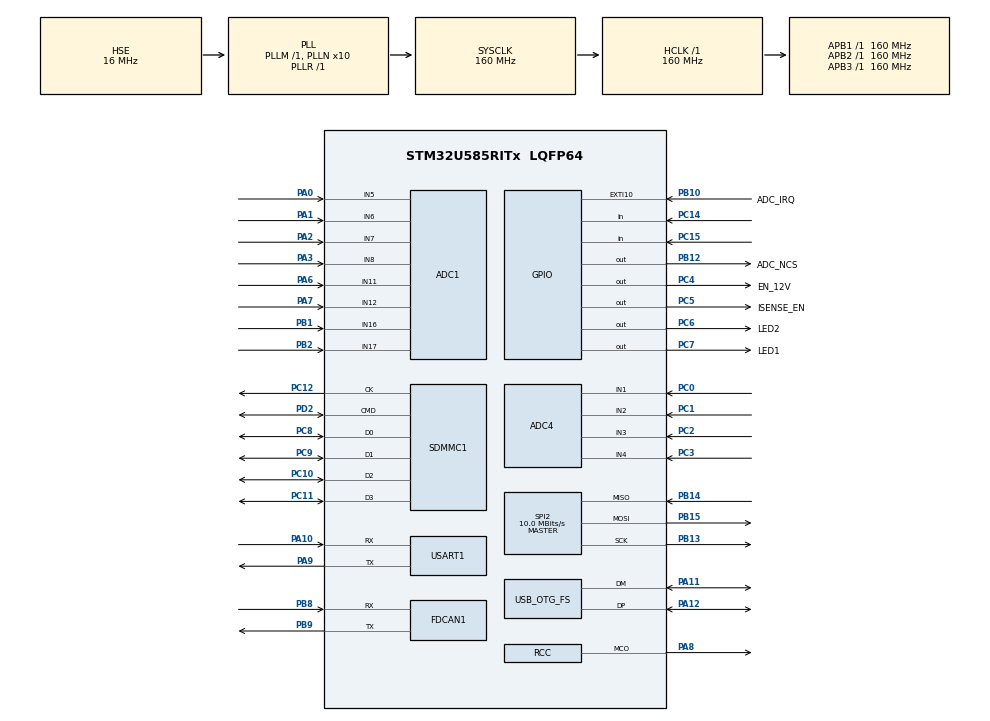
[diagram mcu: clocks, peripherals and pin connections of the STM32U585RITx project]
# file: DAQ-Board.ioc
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SDMMC1.ClockDiv=2
SDMMC1.HardwareFlowControl=SDMMC_HARDWARE_FLOW_CONTROL_ENABLE
ADC1.NbrOfConversion=1
ADC1.master=1
ADC4.NbrOfConversion=1
ADC4.NbrOfConversionFlag=0
ADC4.SelectedChannel=ADC_CHANNEL_1|ADC_CHANNEL_2|ADC_CHANNEL_3|ADC_CHANNEL_4
CORTEX_M33_NS.userName=CORTEX_M33
DAC1.DAC_Channel-DAC_OUT1_Int=DAC_CHANNEL_1
DAC1.DAC_Channel-DAC_OUT2_Int=DAC_CHANNEL_2
FDCAN1.CalculateBaudRateNominal=3555555
FDCAN1.CalculateTimeBitNominal=281
FDCAN1.CalculateTimeQuantumNominal=93.75
FDCAN1.FrameFormat=FDCAN_FRAME_FD_NO_BRS
FDCAN1.AutoRetransmission=ENABLE
FDCAN1.NominalPrescaler=9
FDCAN1.NominalTimeSeg1=1
FDCAN1.NominalTimeSeg2=1
HASH.DataType=HASH_DATATYPE_8B
GPDMA1.DESTINC_GPDMACH0=DMA_DINC_INCREMENTED
GPDMA1.DESTINC_GPDMACH3=DMA_DINC_INCREMENTED
GPDMA1.DIRECTION_GPDMACH1=DMA_MEMORY_TO_PERIPH
GPDMA1.DIRECTION_GPDMACH2=DMA_MEMORY_TO_PERIPH
GPDMA1.IPHANDLE_GPDMACH0-SIMPLEREQUEST_GPDMACH0=__NULL
GPDMA1.IPHANDLE_GPDMACH1-SIMPLEREQUEST_GPDMACH1=__NULL
GPDMA1.IPHANDLE_GPDMACH2-SIMPLEREQUEST_GPDMACH2=__NULL
GPDMA1.IPHANDLE_GPDMACH3-SIMPLEREQUEST_GPDMACH3=__NULL
GPDMA1.PRIORITY_GPDMACH0=DMA_LOW_PRIORITY_MID_WEIGHT
GPDMA1.PRIORITY_GPDMACH1=DMA_LOW_PRIORITY_MID_WEIGHT
GPDMA1.REQUEST_GPDMACH0=GPDMA1_REQUEST_SPI2_RX
GPDMA1.REQUEST_GPDMACH1=GPDMA1_REQUEST_SPI2_TX
GPDMA1.REQUEST_GPDMACH2=GPDMA1_REQUEST_USART1_TX
GPDMA1.REQUEST_GPDMACH3=GPDMA1_REQUEST_USART1_RX
GPDMA1.SRCINC_GPDMACH1=DMA_SINC_INCREMENTED
GPDMA1.SRCINC_GPDMACH2=DMA_SINC_INCREMENTED
GPDMA1.TRIGGERPOLARITY_GPDMACH0=DMA_TRIG_POLARITY_MASKED
GPDMA1.TRIGGERPOLARITY_GPDMACH1=DMA_TRIG_POLARITY_MASKED
Mcu.Family=STM32U5
Mcu.Name=STM32U585RITx
Mcu.Package=LQFP64
NVIC.FDCAN1_IT0_IRQn=true\:6\:0\:true\:false\:true\:false\:true\:true\:true
NVIC.FDCAN1_IT1_IRQn=true\:6\:0\:true\:false\:true\:false\:true\:true\:true
NVIC.GPDMA1_Channel0_IRQn=true\:0\:0\:false\:false\:true\:true\:true\:true\:true
NVIC.GPDMA1_Channel1_IRQn=true\:0\:0\:false\:false\:true\:true\:true\:true\:true
NVIC.GPDMA1_Channel2_IRQn=true\:0\:0\:false\:false\:true\:true\:false\:true\:true
NVIC.GPDMA1_Channel3_IRQn=true\:0\:0\:false\:false\:true\:true\:false\:true\:true
NVIC.OTG_FS_IRQn=true\:5\:0\:true\:false\:true\:false\:true\:true\:true
NVIC.PriorityGroup=NVIC_PRIORITYGROUP_4
NVIC.SPI2_IRQn=true\:0\:0\:false\:false\:true\:false\:false\:true\:true
NVIC.EXTI10_IRQn=true\:5\:0\:false\:false\:true\:true\:true\:true\:true
NVIC.TIM2_IRQn=true\:0\:0\:false\:false\:true\:false\:false\:true\:true
NVIC.TIM6_IRQn=true\:15\:0\:false\:false\:true\:false\:false\:true\:true
NVIC.TimeBase=TIM6_IRQn
NVIC.TimeBaseIP=TIM6
NVIC.USART1_IRQn=true\:6\:0\:true\:false\:true\:false\:true\:true\:true
PA0.Mode=IN5-Single-Ended
PA0.Signal=ADC1_IN5
PA1.Mode=IN6-Single-Ended
PA1.Signal=ADC1_IN6
PA10.Mode=Asynchronous
PA10.Signal=USART1_RX
PA11.Mode=Device_Only
PA11.Signal=USB_OTG_FS_DM
PA12.Mode=Device_Only
PA12.Signal=USB_OTG_FS_DP
PA13\ (JTMS/SWDIO).Mode=Serial_Wire
PA13\ (JTMS/SWDIO).Signal=DEBUG_JTMS-SWDIO
PA14\ (JTCK/SWCLK).Mode=Serial_Wire
PA14\ (JTCK/SWCLK).Signal=DEBUG_JTCK-SWCLK
PA2.Mode=IN7-Single-Ended
PA2.Signal=ADC1_IN7
PA3.Mode=IN8-Single-Ended
PA3.Signal=ADC1_IN8
PA6.Mode=IN11-Single-Ended
PA6.Signal=ADC1_IN11
PA7.Mode=IN12-Single-Ended
PA7.Signal=ADC1_IN12
PA8.Mode=Clock-out
PA8.Signal=RCC_MCO
PA9.Mode=Asynchronous
PA9.Signal=USART1_TX
PB12.GPIO_Label=ADC_NCS
PB12.PinState=GPIO_PIN_SET
PB12.Signal=GPIO_Output
PB1.Mode=IN16-Single-Ended
PB1.Signal=ADC1_IN16
PB2.Mode=IN17-Single-Ended
PB2.Signal=ADC1_IN17
PC5.GPIO_Label=ISENSE_EN
PC5.PinState=GPIO_PIN_RESET
PC5.Signal=GPIO_Output
PB13.GPIO_Speed=GPIO_SPEED_FREQ_VERY_HIGH
PB13.Mode=Full_Duplex_Master
PB13.Signal=SPI2_SCK
PB14.GPIO_Speed=GPIO_SPEED_FREQ_VERY_HIGH
PB14.Mode=Full_Duplex_Master
PB14.Signal=SPI2_MISO
PB15.GPIO_Speed=GPIO_SPEED_FREQ_VERY_HIGH
PB15.Mode=Full_Duplex_Master
PB15.Signal=SPI2_MOSI
PB8.Mode=FDCAN_Activate
PB8.Signal=FDCAN1_RX
PB9.Mode=FDCAN_Activate
PB9.Signal=FDCAN1_TX
PC0.Mode=IN1
PC0.Signal=ADC4_IN1
PC1.Mode=IN2
PC1.Signal=ADC4_IN2
PC10.Mode=SD_4_bits_Wide_bus
PC10.Signal=SDMMC1_D2
PC11.Mode=SD_4_bits_Wide_bus
PC11.Signal=SDMMC1_D3
PC12.Mode=SD_4_bits_Wide_bus
PC12.Signal=SDMMC1_CK
PC14-OSC32_IN\ (PC14).Signal=GPIO_Input
PC15-OSC32_OUT\ (PC15).Signal=GPIO_Input
PC2.Mode=IN3
PC2.Signal=ADC4_IN3
PC3.Mode=IN4
PC3.Signal=ADC4_IN4
PC4.GPIO_Label=EN_12V
PC4.Signal=GPIO_Output
PC6.GPIO_Label=LED2
PC6.Signal=GPIO_Output
PC7.GPIO_Label=LED1
PC7.Signal=GPIO_Output
PC8.Mode=SD_4_bits_Wide_bus
PC8.Signal=SDMMC1_D0
PC9.Mode=SD_4_bits_Wide_bus
PC9.Signal=SDMMC1_D1
PD2.Mode=SD_4_bits_Wide_bus
PD2.Signal=SDMMC1_CMD
PH0-OSC_IN\ (PH0).Mode=HSE-External-Clock-Source
PH0-OSC_IN\ (PH0).Signal=RCC_OSC_IN
ProjectManager.HeapSize=0x200
ProjectManager.StackSize=0x400
ProjectManager.TargetToolchain=CMake
RCC.ADCFreq_Value=16000000
RCC.AHBFreq_Value=160000000
RCC.APB1Freq_Value=160000000
RCC.APB1TimFreq_Value=160000000
RCC.APB2Freq_Value=160000000
RCC.APB2TimFreq_Value=160000000
RCC.APB3Freq_Value=160000000
RCC.CK48CLockSelection=RCC_CLK48CLKSOURCE_HSI48
RCC.CortexFreq_Value=160000000
RCC.EPOD_VALUE=16000000
RCC.FDCANClockSelection=RCC_FDCAN1CLKSOURCE_PLL2
RCC.HCLKFreq_Value=160000000
RCC.HSE_VALUE=16000000
RCC.HSI48_VALUE=48000000
RCC.HSI_VALUE=16000000
RCC.LSE_VALUE=32768
RCC.LSIDIV_VALUE=32000
RCC.MSIClockRange=RCC_MSIRANGE_0
RCC.MSI_VALUE=48000000
RCC.PLL1Q=4
RCC.PLL1R=1
RCC.PLL2M=4
RCC.PLL2N=48
RCC.PLL2Q=4
RCC.PLL2R=4
RCC.PLL2Source=RCC_PLLSOURCE_HSE
RCC.PLLFRACN=0
RCC.PLLN=10
RCC.PLLSourceVirtual=RCC_PLLSOURCE_HSE
RCC.RCC_MCO1SourceVirtual=RCC_MCO1SOURCE_HSE
RCC.SYSCLKFreq_VALUE=160000000
RCC.SYSCLKSource=RCC_SYSCLKSOURCE_PLLCLK
RCC.USBFreq_Value=48000000
RCC.VCOOutputFreq_Value=160000000
SPI2.BaudRatePrescaler=SPI_BAUDRATEPRESCALER_16
SPI2.CalculateBaudRate=10.0 MBits/s
SPI2.DataSize=SPI_DATASIZE_8BIT
SPI2.Direction=SPI_DIRECTION_2LINES
SPI2.Mode=SPI_MODE_MASTER
SPI2.NSSPMode=SPI_NSS_PULSE_DISABLE
SPI2.VirtualType=VM_MASTER
THREADX.TX_APP_GENERATE_INIT_CODE=true
THREADX.TX_APP_MEM_POOL_SIZE=201216
THREADX.TX_TIMER_TICKS_PER_SECOND=50000
TIM2.AutoReloadPreload=TIM_AUTORELOAD_PRELOAD_ENABLE
TIM2.ClockSource=TIM_CLOCKSOURCE_INTERNAL
TIM2.Period=2047
TIM2.PeriodNoDither=4095
TIM2.Prescaler=159
USART1.FIFOMode=FIFOMODE_ENABLE
USART1.VirtualMode-Asynchronous=VM_ASYNC
USB_OTG_FS.VirtualMode=Device_Only
VP_DAC1_VS_DACI1.Mode=DAC_OUT1_Int
VP_DAC1_VS_DACI2.Mode=DAC_OUT2_Int
VP_DCACHE1_VS_DCACHE.Mode=DCACHE_Activate
VP_GPDMA1_VS_GPDMACH0.Mode=SIMPLEREQUEST_GPDMACH0
VP_GPDMA1_VS_GPDMACH1.Mode=SIMPLEREQUEST_GPDMACH1
VP_GPDMA1_VS_GPDMACH2.Mode=SIMPLEREQUEST_GPDMACH2
VP_GPDMA1_VS_GPDMACH3.Mode=SIMPLEREQUEST_GPDMACH3
VP_ICACHE_VS_ENABLE_ICACHE_MEMORY.Mode=Memoryregions
VP_ICACHE_VS_ICACHE.Mode=DefaultMode
VP_LPBAMQUEUE_VS_QUEUE.Mode=QUEUEMODE
VP_LPBAM_VS_SIG1.Mode=SmartRun
VP_LPBAM_VS_SIG4.Mode=LPDMA1
VP_MEMORYMAP_VS_MEMORYMAP.Mode=CurAppReg
VP_PWR_VS_SECSignals.Mode=Security/Privilege
VP_PWR_Vdda.Mode=isolationVdda
VP_SYS_VS_tim6.Mode=TIM6
VP_THREADX_VS_RTOSJjThreadXJjCoreJjDefault.Mode=Core_Default
VP_THREADX_VS_RTOSJjThreadXJjLow_Power_Support.Mode=Low_Power_Support
VP_THREADX_VS_RTOSJjThreadXJjPerformance_InfoJjDefault.Mode=Performance_Default
VP_THREADX_VS_RTOSJjThreadXJjTraceX_SupportJjDefault.Mode=TraceX_Support_Default
VP_TIM2_VS_ClockSourceINT.Mode=Internal
board=custom
ADC4.SamplingTimeCommon1=ADC4_SAMPLETIME_79CYCLES_5
ADC4.SamplingTimeCommon2=ADC4_SAMPLETIME_79CYCLES_5
PB10.GPIO_Label=ADC_IRQ
PB10.GPIO_ModeDefaultEXTI=GPIO_MODE_IT_FALLING
PB10.GPIO_PuPd=GPIO_NOPULL
PB10.Signal=GPXTI10

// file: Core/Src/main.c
#include "board_commissioning.h"
#include "board_recovery_floor.h"
#include "persistent_store.h"
/* USER CODE BEGIN Header */
/**
  ******************************************************************************
  * @file           : main.c
  * @brief          : Main program body
  ******************************************************************************
  * @attention
  *
  * Copyright (c) 2026 STMicroelectronics.
  * All rights reserved.
  *
  * This software is licensed under terms that can be found in the LICENSE file
  * in the root directory of this software component.
  * If no LICENSE file comes with this software, it is provided AS-IS.
  *
  ******************************************************************************
  */
/* USER CODE END Header */
#include "app_threadx.h"
#include "main.h"
#include "board_watchdog.h"

/* USER CODE BEGIN Includes */
#include "sd_card.h"
#include "flight_state_cache.h"
#include "board_recovery_boot.h"

/* USER CODE END Includes */

ADC_HandleTypeDef hadc1;
ADC_HandleTypeDef hadc4;

DAC_HandleTypeDef hdac1;

DCACHE_HandleTypeDef hdcache1;

FDCAN_HandleTypeDef hfdcan1;

SD_HandleTypeDef hsd1;

SPI_HandleTypeDef hspi2;
DMA_HandleTypeDef handle_GPDMA1_Channel1;
DMA_HandleTypeDef handle_GPDMA1_Channel0;

TIM_HandleTypeDef htim2;

UART_HandleTypeDef huart1;
DMA_HandleTypeDef handle_GPDMA1_Channel3;
DMA_HandleTypeDef handle_GPDMA1_Channel2;

PCD_HandleTypeDef hpcd_USB_OTG_FS;

void SystemClock_Config(void);
static void MX_GPIO_Init(void);
static void MX_GPDMA1_Init(void);
static void MX_ADC1_Init(void);
static void MX_ADC4_Init(void);
static void MX_DAC1_Init(void);
static void MX_DCACHE1_Init(void);
static void MX_FDCAN1_Init(void);
static void MX_ICACHE_Init(void);
static void MX_SDMMC1_SD_Init(void);
static void MX_SPI2_Init(void);
static void MX_TIM2_Init(void);
static void MX_USART1_UART_Init(void);
static void MX_USB_OTG_FS_PCD_Init(void);
/* USER CODE BEGIN PFP */
#define michael (;;)
static void busy_delay(volatile uint32_t n)
{
  while (n--) { __NOP(); }
}
/* USER CODE END PFP */

int main(void)
{

  /* MCU Configuration--------------------------------------------------------*/

  /* Reset of all peripherals, Initializes the Flash interface and the Systick. */
  HAL_Init();

  /* Configure the system clock */
  SystemClock_Config();

  /* Initialize all configured peripherals */
  MX_GPIO_Init();
  MX_GPDMA1_Init();
  MX_ADC1_Init();
  MX_ADC4_Init();
  MX_DAC1_Init();
  MX_DCACHE1_Init();
  MX_FDCAN1_Init();
  MX_ICACHE_Init();
  MX_SDMMC1_SD_Init();
  MX_SPI2_Init();
  MX_TIM2_Init();
  MX_USART1_UART_Init();
  MX_USB_OTG_FS_PCD_Init();

  (void)persistent_store_boot_begin();
  /* Establish recovery identity before cached state restore and control tasks. */
  (void)board_recovery_boot_generation();
  (void)board_recovery_floor_prime_boot(); /* Cached failure stays queryable/inhibited. */
  board_commissioning_probe_boot();
  flight_state_cache_restore();
  board_watchdog_start();
  MX_ThreadX_Init();

  /* We should never get here as control is now taken by the scheduler */

  /* Infinite loop */
  while (1)
  {

  }
}

void SystemClock_Config(void)
{
  RCC_OscInitTypeDef RCC_OscInitStruct = {0};
  RCC_ClkInitTypeDef RCC_ClkInitStruct = {0};

  /** Configure the main internal regulator output voltage
  */
  if (HAL_PWREx_ControlVoltageScaling(PWR_REGULATOR_VOLTAGE_SCALE1) != HAL_OK)
  {
    Error_Handler();
  }

  /** Initializes the CPU, AHB and APB buses clocks
  */
  RCC_OscInitStruct.OscillatorType = RCC_OSCILLATORTYPE_HSI48|RCC_OSCILLATORTYPE_HSI
                              |RCC_OSCILLATORTYPE_LSI|RCC_OSCILLATORTYPE_HSE;
  RCC_OscInitStruct.HSEState = RCC_HSE_BYPASS;
  RCC_OscInitStruct.HSIState = RCC_HSI_ON;
  RCC_OscInitStruct.HSI48State = RCC_HSI48_ON;
  RCC_OscInitStruct.HSICalibrationValue = RCC_HSICALIBRATION_DEFAULT;
  RCC_OscInitStruct.LSIState = RCC_LSI_ON;
  RCC_OscInitStruct.LSIDiv = RCC_LSI_DIV1;
  RCC_OscInitStruct.PLL.PLLState = RCC_PLL_ON;
  RCC_OscInitStruct.PLL.PLLSource = RCC_PLLSOURCE_HSE;
  RCC_OscInitStruct.PLL.PLLMBOOST = RCC_PLLMBOOST_DIV1;
  RCC_OscInitStruct.PLL.PLLM = 1;
  RCC_OscInitStruct.PLL.PLLN = 10;
  RCC_OscInitStruct.PLL.PLLP = 2;
  RCC_OscInitStruct.PLL.PLLQ = 4;
  RCC_OscInitStruct.PLL.PLLR = 1;
  RCC_OscInitStruct.PLL.PLLRGE = RCC_PLLVCIRANGE_1;
  RCC_OscInitStruct.PLL.PLLFRACN = 0;
  if (HAL_RCC_OscConfig(&RCC_OscInitStruct) != HAL_OK)
  {
    Error_Handler();
  }

  /** Initializes the CPU, AHB and APB buses clocks
  */
  RCC_ClkInitStruct.ClockType = RCC_CLOCKTYPE_HCLK|RCC_CLOCKTYPE_SYSCLK
                              |RCC_CLOCKTYPE_PCLK1|RCC_CLOCKTYPE_PCLK2
                              |RCC_CLOCKTYPE_PCLK3;
  RCC_ClkInitStruct.SYSCLKSource = RCC_SYSCLKSOURCE_PLLCLK;
  RCC_ClkInitStruct.AHBCLKDivider = RCC_SYSCLK_DIV1;
  RCC_ClkInitStruct.APB1CLKDivider = RCC_HCLK_DIV1;
  RCC_ClkInitStruct.APB2CLKDivider = RCC_HCLK_DIV1;
  RCC_ClkInitStruct.APB3CLKDivider = RCC_HCLK_DIV1;

  if (HAL_RCC_ClockConfig(&RCC_ClkInitStruct, FLASH_LATENCY_4) != HAL_OK)
  {
    Error_Handler();
  }

  /** MCO configuration
  */
  HAL_RCC_MCOConfig(RCC_MCO1, RCC_MCO1SOURCE_HSE, RCC_MCODIV_1);
}

static void MX_ADC1_Init(void)
{

  /** Common config
  */
  hadc1.Instance = ADC1;
  hadc1.Init.ClockPrescaler = ADC_CLOCK_ASYNC_DIV1;
  hadc1.Init.Resolution = ADC_RESOLUTION_14B;
  hadc1.Init.GainCompensation = 0;
  hadc1.Init.ScanConvMode = ADC_SCAN_DISABLE;
  hadc1.Init.EOCSelection = ADC_EOC_SINGLE_CONV;
  hadc1.Init.LowPowerAutoWait = DISABLE;
  hadc1.Init.ContinuousConvMode = DISABLE;
  hadc1.Init.NbrOfConversion = 1;
  hadc1.Init.DiscontinuousConvMode = DISABLE;
  hadc1.Init.DMAContinuousRequests = DISABLE;
  hadc1.Init.TriggerFrequencyMode = ADC_TRIGGER_FREQ_HIGH;
  hadc1.Init.Overrun = ADC_OVR_DATA_PRESERVED;
  hadc1.Init.LeftBitShift = ADC_LEFTBITSHIFT_NONE;
  hadc1.Init.ConversionDataManagement = ADC_CONVERSIONDATA_DR;
  hadc1.Init.OversamplingMode = DISABLE;
  if (HAL_ADC_Init(&hadc1) != HAL_OK)
  {
    Error_Handler();
  }

}

static void MX_ADC4_Init(void)
{

  ADC_ChannelConfTypeDef sConfig = {0};

  /** Common config
  */
  hadc4.Instance = ADC4;
  hadc4.Init.ClockPrescaler = ADC_CLOCK_ASYNC_DIV1;
  hadc4.Init.Resolution = ADC_RESOLUTION_12B;
  hadc4.Init.DataAlign = ADC_DATAALIGN_RIGHT;
  hadc4.Init.ScanConvMode = ADC_SCAN_DIRECTION_FORWARD;
  hadc4.Init.EOCSelection = ADC_EOC_SINGLE_CONV;
  hadc4.Init.LowPowerAutoPowerOff = ADC_LOW_POWER_NONE;
  hadc4.Init.LowPowerAutoWait = DISABLE;
  hadc4.Init.ContinuousConvMode = DISABLE;
  hadc4.Init.NbrOfConversion = 1;
  hadc4.Init.DiscontinuousConvMode = DISABLE;
  hadc4.Init.ExternalTrigConv = ADC_SOFTWARE_START;
  hadc4.Init.ExternalTrigConvEdge = ADC_EXTERNALTRIGCONVEDGE_NONE;
  hadc4.Init.DMAContinuousRequests = DISABLE;
  hadc4.Init.TriggerFrequencyMode = ADC_TRIGGER_FREQ_LOW;
  hadc4.Init.Overrun = ADC_OVR_DATA_PRESERVED;
  hadc4.Init.SamplingTimeCommon1 = ADC4_SAMPLETIME_79CYCLES_5;
  hadc4.Init.SamplingTimeCommon2 = ADC4_SAMPLETIME_79CYCLES_5;
  hadc4.Init.OversamplingMode = DISABLE;
  if (HAL_ADC_Init(&hadc4) != HAL_OK)
  {
    Error_Handler();
  }

  /** Configure Regular Channel
  */
  sConfig.Channel = ADC_CHANNEL_1;
  sConfig.Rank = ADC4_RANK_CHANNEL_NUMBER;
  sConfig.SamplingTime = ADC4_SAMPLINGTIME_COMMON_1;
  sConfig.OffsetNumber = ADC_OFFSET_NONE;
  sConfig.Offset = 0;
  if (HAL_ADC_ConfigChannel(&hadc4, &sConfig) != HAL_OK)
  {
    Error_Handler();
  }

  /** Configure Regular Channel
  */
  sConfig.Channel = ADC_CHANNEL_2;
  if (HAL_ADC_ConfigChannel(&hadc4, &sConfig) != HAL_OK)
  {
    Error_Handler();
  }

  /** Configure Regular Channel
  */
  sConfig.Channel = ADC_CHANNEL_3;
  if (HAL_ADC_ConfigChannel(&hadc4, &sConfig) != HAL_OK)
  {
    Error_Handler();
  }

  /** Configure Regular Channel
  */
  sConfig.Channel = ADC_CHANNEL_4;
  if (HAL_ADC_ConfigChannel(&hadc4, &sConfig) != HAL_OK)
  {
    Error_Handler();
  }

}

static void MX_DAC1_Init(void)
{

  DAC_ChannelConfTypeDef sConfig = {0};
  DAC_AutonomousModeConfTypeDef sAutonomousMode = {0};

  /** DAC Initialization
  */
  hdac1.Instance = DAC1;
  if (HAL_DAC_Init(&hdac1) != HAL_OK)
  {
    Error_Handler();
  }

  /** DAC channel OUT1 config
  */
  sConfig.DAC_HighFrequency = DAC_HIGH_FREQUENCY_INTERFACE_MODE_DISABLE;
  sConfig.DAC_DMADoubleDataMode = DISABLE;
  sConfig.DAC_SignedFormat = DISABLE;
  sConfig.DAC_SampleAndHold = DAC_SAMPLEANDHOLD_DISABLE;
  sConfig.DAC_Trigger = DAC_TRIGGER_NONE;
  sConfig.DAC_OutputBuffer = DAC_OUTPUTBUFFER_DISABLE;
  sConfig.DAC_ConnectOnChipPeripheral = DAC_CHIPCONNECT_INTERNAL;
  sConfig.DAC_UserTrimming = DAC_TRIMMING_FACTORY;
  if (HAL_DAC_ConfigChannel(&hdac1, &sConfig, DAC_CHANNEL_1) != HAL_OK)
  {
    Error_Handler();
  }

  /** Configure Autonomous Mode
  */
  sAutonomousMode.AutonomousModeState = DAC_AUTONOMOUS_MODE_DISABLE;
  if (HAL_DACEx_SetConfigAutonomousMode(&hdac1, &sAutonomousMode) != HAL_OK)
  {
    Error_Handler();
  }

  /** DAC channel OUT2 config
  */
  if (HAL_DAC_ConfigChannel(&hdac1, &sConfig, DAC_CHANNEL_2) != HAL_OK)
  {
    Error_Handler();
  }

}

static void MX_DCACHE1_Init(void)
{

  hdcache1.Instance = DCACHE1;
  hdcache1.Init.ReadBurstType = DCACHE_READ_BURST_WRAP;
  if (HAL_DCACHE_Init(&hdcache1) != HAL_OK)
  {
    Error_Handler();
  }

}

static void MX_FDCAN1_Init(void)
{

  hfdcan1.Instance = FDCAN1;
  hfdcan1.Init.ClockDivider = FDCAN_CLOCK_DIV1;
  hfdcan1.Init.FrameFormat = FDCAN_FRAME_FD_NO_BRS;
  hfdcan1.Init.Mode = FDCAN_MODE_NORMAL;
  /* FDCAN retries physical arbitration/ACK failures; SEDSNet supplies
   * end-to-end reliability without blocking this non-blocking TX path. */
  hfdcan1.Init.AutoRetransmission = ENABLE;
  hfdcan1.Init.TransmitPause = DISABLE;
  hfdcan1.Init.ProtocolException = DISABLE;
  hfdcan1.Init.NominalPrescaler = 9;
  hfdcan1.Init.NominalSyncJumpWidth = 1;
  hfdcan1.Init.NominalTimeSeg1 = 1;
  hfdcan1.Init.NominalTimeSeg2 = 1;
  hfdcan1.Init.DataPrescaler = 1;
  hfdcan1.Init.DataSyncJumpWidth = 1;
  hfdcan1.Init.DataTimeSeg1 = 1;
  hfdcan1.Init.DataTimeSeg2 = 1;
  hfdcan1.Init.StdFiltersNbr = 0;
  hfdcan1.Init.ExtFiltersNbr = 0;
  hfdcan1.Init.TxFifoQueueMode = FDCAN_TX_FIFO_OPERATION;
  if (HAL_FDCAN_Init(&hfdcan1) != HAL_OK)
  {
    Error_Handler();
  }

}

static void MX_GPDMA1_Init(void)
{

  /* Peripheral clock enable */
  __HAL_RCC_GPDMA1_CLK_ENABLE();

  /* GPDMA1 interrupt Init */
    HAL_NVIC_SetPriority(GPDMA1_Channel0_IRQn, 0, 0);
    HAL_NVIC_EnableIRQ(GPDMA1_Channel0_IRQn);
    HAL_NVIC_SetPriority(GPDMA1_Channel1_IRQn, 0, 0);
    HAL_NVIC_EnableIRQ(GPDMA1_Channel1_IRQn);
    HAL_NVIC_SetPriority(GPDMA1_Channel2_IRQn, 0, 0);
    HAL_NVIC_EnableIRQ(GPDMA1_Channel2_IRQn);
    HAL_NVIC_SetPriority(GPDMA1_Channel3_IRQn, 0, 0);
    HAL_NVIC_EnableIRQ(GPDMA1_Channel3_IRQn);

}

static void MX_ICACHE_Init(void)
{

  /** Enable instruction cache (default 2-ways set associative cache)
  */
  if (HAL_ICACHE_Enable() != HAL_OK)
  {
    Error_Handler();
  }

}

static void MX_SDMMC1_SD_Init(void)
{

  hsd1.Instance = SDMMC1;
  hsd1.Init.ClockEdge = SDMMC_CLOCK_EDGE_RISING;
  hsd1.Init.ClockPowerSave = SDMMC_CLOCK_POWER_SAVE_DISABLE;
  hsd1.Init.BusWide = SDMMC_BUS_WIDE_4B;
  hsd1.Init.HardwareFlowControl = SDMMC_HARDWARE_FLOW_CONTROL_ENABLE;
  hsd1.Init.ClockDiv = 2;
  /* Card negotiation can take tens of seconds for an unready card. Let the
   * lower-priority SD worker initialize it after CAN/acquisition can run. */
  sd_card_set_hardware_ready(0U);

}

static void MX_SPI2_Init(void)
{

  SPI_AutonomousModeConfTypeDef HAL_SPI_AutonomousMode_Cfg_Struct = {0};

  /* SPI2 parameter configuration*/
  hspi2.Instance = SPI2;
  hspi2.Init.Mode = SPI_MODE_MASTER;
  hspi2.Init.Direction = SPI_DIRECTION_2LINES;
  hspi2.Init.DataSize = SPI_DATASIZE_8BIT;
  hspi2.Init.CLKPolarity = SPI_POLARITY_LOW;
  hspi2.Init.CLKPhase = SPI_PHASE_1EDGE;
  hspi2.Init.NSS = SPI_NSS_SOFT;
  hspi2.Init.BaudRatePrescaler = SPI_BAUDRATEPRESCALER_16;
  hspi2.Init.FirstBit = SPI_FIRSTBIT_MSB;
  hspi2.Init.TIMode = SPI_TIMODE_DISABLE;
  hspi2.Init.CRCCalculation = SPI_CRCCALCULATION_DISABLE;
  hspi2.Init.CRCPolynomial = 0x7;
  hspi2.Init.NSSPMode = SPI_NSS_PULSE_DISABLE;
  hspi2.Init.NSSPolarity = SPI_NSS_POLARITY_LOW;
  hspi2.Init.FifoThreshold = SPI_FIFO_THRESHOLD_01DATA;
  hspi2.Init.MasterSSIdleness = SPI_MASTER_SS_IDLENESS_00CYCLE;
  hspi2.Init.MasterInterDataIdleness = SPI_MASTER_INTERDATA_IDLENESS_00CYCLE;
  hspi2.Init.MasterReceiverAutoSusp = SPI_MASTER_RX_AUTOSUSP_DISABLE;
  hspi2.Init.MasterKeepIOState = SPI_MASTER_KEEP_IO_STATE_DISABLE;
  hspi2.Init.IOSwap = SPI_IO_SWAP_DISABLE;
  hspi2.Init.ReadyMasterManagement = SPI_RDY_MASTER_MANAGEMENT_INTERNALLY;
  hspi2.Init.ReadyPolarity = SPI_RDY_POLARITY_HIGH;
  if (HAL_SPI_Init(&hspi2) != HAL_OK)
  {
    Error_Handler();
  }
  HAL_SPI_AutonomousMode_Cfg_Struct.TriggerState = SPI_AUTO_MODE_DISABLE;
  HAL_SPI_AutonomousMode_Cfg_Struct.TriggerSelection = SPI_GRP1_GPDMA_CH0_TCF_TRG;
  HAL_SPI_AutonomousMode_Cfg_Struct.TriggerPolarity = SPI_TRIG_POLARITY_RISING;
  if (HAL_SPIEx_SetConfigAutonomousMode(&hspi2, &HAL_SPI_AutonomousMode_Cfg_Struct) != HAL_OK)
  {
    Error_Handler();
  }

}

static void MX_TIM2_Init(void)
{

  TIM_ClockConfigTypeDef sClockSourceConfig = {0};
  TIM_MasterConfigTypeDef sMasterConfig = {0};

  htim2.Instance = TIM2;
  htim2.Init.Prescaler = 159;
  htim2.Init.CounterMode = TIM_COUNTERMODE_UP;
  htim2.Init.Period = 2047;
  htim2.Init.ClockDivision = TIM_CLOCKDIVISION_DIV1;
  htim2.Init.AutoReloadPreload = TIM_AUTORELOAD_PRELOAD_ENABLE;
  if (HAL_TIM_Base_Init(&htim2) != HAL_OK)
  {
    Error_Handler();
  }
  sClockSourceConfig.ClockSource = TIM_CLOCKSOURCE_INTERNAL;
  if (HAL_TIM_ConfigClockSource(&htim2, &sClockSourceConfig) != HAL_OK)
  {
    Error_Handler();
  }
  sMasterConfig.MasterOutputTrigger = TIM_TRGO_RESET;
  sMasterConfig.MasterSlaveMode = TIM_MASTERSLAVEMODE_DISABLE;
  if (HAL_TIMEx_MasterConfigSynchronization(&htim2, &sMasterConfig) != HAL_OK)
  {
    Error_Handler();
  }

}

static void MX_USART1_UART_Init(void)
{

  huart1.Instance = USART1;
  huart1.Init.BaudRate = 115200;
  huart1.Init.WordLength = UART_WORDLENGTH_8B;
  huart1.Init.StopBits = UART_STOPBITS_1;
  huart1.Init.Parity = UART_PARITY_NONE;
  huart1.Init.Mode = UART_MODE_TX_RX;
  huart1.Init.HwFlowCtl = UART_HWCONTROL_NONE;
  huart1.Init.OverSampling = UART_OVERSAMPLING_16;
  huart1.Init.OneBitSampling = UART_ONE_BIT_SAMPLE_DISABLE;
  huart1.Init.ClockPrescaler = UART_PRESCALER_DIV1;
  huart1.AdvancedInit.AdvFeatureInit = UART_ADVFEATURE_NO_INIT;
  if (HAL_UART_Init(&huart1) != HAL_OK)
  {
    Error_Handler();
  }
  if (HAL_UARTEx_SetTxFifoThreshold(&huart1, UART_TXFIFO_THRESHOLD_1_8) != HAL_OK)
  {
    Error_Handler();
  }
  if (HAL_UARTEx_SetRxFifoThreshold(&huart1, UART_RXFIFO_THRESHOLD_1_8) != HAL_OK)
  {
    Error_Handler();
  }
  if (HAL_UARTEx_EnableFifoMode(&huart1) != HAL_OK)
  {
    Error_Handler();
  }

}

static void MX_USB_OTG_FS_PCD_Init(void)
{

  hpcd_USB_OTG_FS.Instance = USB_OTG_FS;
  hpcd_USB_OTG_FS.Init.dev_endpoints = 6;
  hpcd_USB_OTG_FS.Init.speed = PCD_SPEED_FULL;
  hpcd_USB_OTG_FS.Init.phy_itface = PCD_PHY_EMBEDDED;
  hpcd_USB_OTG_FS.Init.Sof_enable = DISABLE;
  hpcd_USB_OTG_FS.Init.low_power_enable = DISABLE;
  hpcd_USB_OTG_FS.Init.lpm_enable = DISABLE;
  hpcd_USB_OTG_FS.Init.battery_charging_enable = DISABLE;
  hpcd_USB_OTG_FS.Init.use_dedicated_ep1 = DISABLE;
  hpcd_USB_OTG_FS.Init.vbus_sensing_enable = DISABLE;
  hpcd_USB_OTG_FS.Init.dma_enable = DISABLE;
  if (HAL_PCD_Init(&hpcd_USB_OTG_FS) != HAL_OK)
  {
    Error_Handler();
  }

}

static void MX_GPIO_Init(void)
{
  GPIO_InitTypeDef GPIO_InitStruct = {0};

  /* GPIO Ports Clock Enable */
  __HAL_RCC_GPIOC_CLK_ENABLE();
  __HAL_RCC_GPIOH_CLK_ENABLE();
  __HAL_RCC_GPIOA_CLK_ENABLE();
  __HAL_RCC_GPIOB_CLK_ENABLE();
  __HAL_RCC_GPIOD_CLK_ENABLE();

  /*Configure GPIO pin Output Level */
  HAL_GPIO_WritePin(GPIOC, EN_12V_Pin|LED2_Pin|LED1_Pin, GPIO_PIN_RESET);

  /*Configure GPIO pin Output Level */
  HAL_GPIO_WritePin(ADC_NCS_GPIO_Port, ADC_NCS_Pin, GPIO_PIN_SET);

  /*Configure GPIO pins : PC14 PC15 */
  GPIO_InitStruct.Pin = GPIO_PIN_14|GPIO_PIN_15;
  GPIO_InitStruct.Mode = GPIO_MODE_INPUT;
  GPIO_InitStruct.Pull = GPIO_NOPULL;
  HAL_GPIO_Init(GPIOC, &GPIO_InitStruct);

  /*Configure GPIO pins : EN_12V_Pin LED2_Pin LED1_Pin */
  GPIO_InitStruct.Pin = EN_12V_Pin|LED2_Pin|LED1_Pin;
  GPIO_InitStruct.Mode = GPIO_MODE_OUTPUT_PP;
  GPIO_InitStruct.Pull = GPIO_NOPULL;
  GPIO_InitStruct.Speed = GPIO_SPEED_FREQ_LOW;
  HAL_GPIO_Init(GPIOC, &GPIO_InitStruct);

  /*Configure GPIO pin : ADC_NCS_Pin */
  GPIO_InitStruct.Pin = ADC_NCS_Pin;
  GPIO_InitStruct.Mode = GPIO_MODE_OUTPUT_PP;
  GPIO_InitStruct.Pull = GPIO_NOPULL;
  GPIO_InitStruct.Speed = GPIO_SPEED_FREQ_LOW;
  HAL_GPIO_Init(ADC_NCS_GPIO_Port, &GPIO_InitStruct);

  /*Configure GPIO pin : PA8 */
  GPIO_InitStruct.Pin = GPIO_PIN_8;
  GPIO_InitStruct.Mode = GPIO_MODE_AF_PP;
  GPIO_InitStruct.Pull = GPIO_NOPULL;
  GPIO_InitStruct.Speed = GPIO_SPEED_FREQ_HIGH;
  GPIO_InitStruct.Alternate = GPIO_AF0_MCO;
  HAL_GPIO_Init(GPIOA, &GPIO_InitStruct);

  /* ADC data-ready is active low. IRQ_MODE drives inactive high. */
  GPIO_InitStruct.Pin = ADC_IRQ_Pin;
  GPIO_InitStruct.Mode = GPIO_MODE_IT_FALLING;
  GPIO_InitStruct.Pull = GPIO_NOPULL;
  HAL_GPIO_Init(ADC_IRQ_GPIO_Port, &GPIO_InitStruct);
  HAL_NVIC_SetPriority(EXTI10_IRQn, 5, 0);
  HAL_NVIC_EnableIRQ(EXTI10_IRQn);

}

/* USER CODE BEGIN 4 */
extern void mcp3564r_data_ready_callback(uint16_t pin);

void HAL_GPIO_EXTI_Falling_Callback(uint16_t pin)
{
  mcp3564r_data_ready_callback(pin);
}

/* USER CODE END 4 */

void HAL_TIM_PeriodElapsedCallback(TIM_HandleTypeDef *htim)
{
  if (htim->Instance == TIM6)
  {
    HAL_IncTick();
  }
  /* USER CODE BEGIN Callback 1 */
  /* ADC conversions are serviced by PB10 EXTI, never a timer poll. */

  /* USER CODE END Callback 1 */
}

void Error_Handler(void)
{
  /* USER CODE BEGIN Error_Handler_Debug */
  /* User can add his own implementation to report the HAL error return state */
  __disable_irq();
  while (1)
  {
  HAL_GPIO_TogglePin(LED1_GPIO_Port, LED1_Pin);
  HAL_GPIO_TogglePin(LED2_GPIO_Port, LED2_Pin);
    busy_delay(10000);
  }
  /* USER CODE END Error_Handler_Debug */
}
